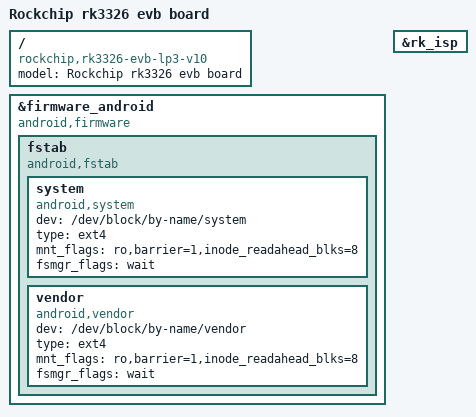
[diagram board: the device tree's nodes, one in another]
// SPDX-License-Identifier: (GPL-2.0+ OR MIT)
/*
 * Copyright (c) 2017 Fuzhou Rockchip Electronics Co., Ltd
 */

/dts-v1/;
#include "rk3326-evb-lp3-v10.dtsi"

/ {
	model = "Rockchip rk3326 evb board";
	compatible = "rockchip,rk3326-evb-lp3-v10", "rockchip,rk3326";
};

&firmware_android {
	compatible = "android,firmware";
	fstab {
		compatible = "android,fstab";
		system {
			compatible = "android,system";
			dev = "/dev/block/by-name/system";
			type = "ext4";
			mnt_flags = "ro,barrier=1,inode_readahead_blks=8";
			fsmgr_flags = "wait";
		};
		vendor {
			compatible = "android,vendor";
			dev = "/dev/block/by-name/vendor";
			type = "ext4";
			mnt_flags = "ro,barrier=1,inode_readahead_blks=8";
			fsmgr_flags = "wait";
		};
	};
};

&rk_isp {
	status = "okay";
};
